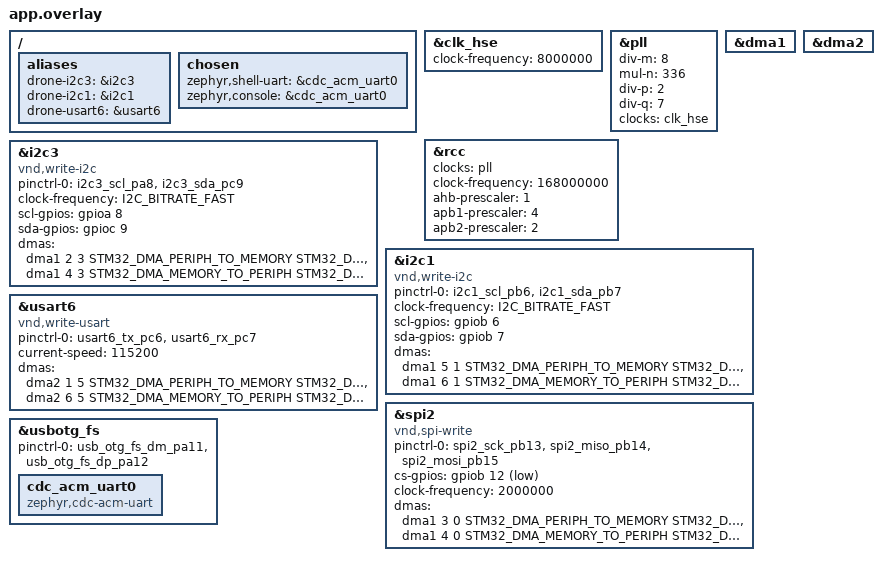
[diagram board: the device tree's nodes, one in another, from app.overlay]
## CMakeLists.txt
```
cmake_minimum_required(VERSION 3.20.0)

list(APPEND DTS_ROOTS "${CMAKE_CURRENT_SOURCE_DIR}")

# Tự động tìm kiếm cấu hình môi trường gốc của Zephyr OS
find_package(Zephyr REQUIRED HINTS $ENV{ZEPHYR_BASE})

project(Drone_Mini_Ver2)

# Ép sinh ra file compile_commands.json để VS Code hết gạch đỏ
set(CMAKE_EXPORT_COMPILE_COMMANDS ON CACHE INTERNAL "")

zephyr_include_directories(
    src
    src/Initialize
    src/RTOS
    src/Radio_Communication
    src/BMI088_Library
    src/INA226
    src/HMC5883
    src/PMW3901
    src/BMP280
    src/PWM_Control
    src/I2C_Progress
    src/Ranging_Sensor
    src/Ranging_Sensor/core/inc
    src/Ranging_Sensor/core/src
    src/USB_Debugging
    src/Extended_Kalman_Filter
    src/PID
)

# Khai báo nguồn file .c
file(GLOB_RECURSE ALL_SOURCES
    src/*.c
    BMI088_Library/*.c
    RTOS/*.c
    Initialize/*.c
    PWM_Control/*.c
    Radio_Communication/*.c
    PMW3901/*.c
    BMP280/*.c
    INA226/*.c
    HMC5883/*.c
    AT24LC/*.c
    PMW_Control/*.c
    I2C_Progress/*.c
    Ranging_Sensor/*.c
    Ranging_Sensor/core/src/*.c
    USB_Debugging/*.c
    Extended_Kalman_Filter/*.c
    PID/*.c
)

target_sources(app PRIVATE ${ALL_SOURCES})
```

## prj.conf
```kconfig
CONFIG_DYNAMIC_INTERRUPTS=y
CONFIG_SYS_CLOCK_TICKS_PER_SEC=1000
CONFIG_FPU=y
CONFIG_MAIN_STACK_SIZE=2048
CONFIG_SYSTEM_WORKQUEUE_PRIORITY=2

# RTT CONSOLE
CONFIG_USE_SEGGER_RTT=y
CONFIG_RTT_CONSOLE=y
CONFIG_CONSOLE=y
CONFIG_STDOUT_CONSOLE=y
CONFIG_PRINTK=y
CONFIG_SEGGER_RTT_BUFFER_SIZE_UP=1024

CONFIG_GPIO=y
# event & thread info
CONFIG_EVENTS=y
CONFIG_PINCTRL=y
CONFIG_THREAD_STACK_INFO=y
CONFIG_INIT_STACKS=y
CONFIG_THREAD_MONITOR=y

# --- BẬT DRIVER SERIAL & USB CDC ACM ---
CONFIG_SERIAL=y
CONFIG_UART_LINE_CTRL=y
CONFIG_USB_DEVICE_STACK=y
CONFIG_USB_DEVICE_PRODUCT="Drone Shell Console"
CONFIG_USB_CDC_ACM=y
CONFIG_USB_DEVICE_INITIALIZE_AT_BOOT=y


# --- BẬT ZEPHYR SHELL ---
CONFIG_SHELL=y
CONFIG_SHELL_BACKEND_SERIAL=y
CONFIG_SHELL_PROMPT_UART="drone:~$ "
CONFIG_SHELL_STACK_SIZE=3072
CONFIG_CBPRINTF_FP_SUPPORT=y
```

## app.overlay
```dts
#include <zephyr/dt-bindings/pinctrl/stm32-pinctrl.h>
#include <zephyr/dt-bindings/dma/stm32_dma.h>


&clk_hse {
    clock-frequency = <8000000>;
    status = "okay";
};

/* Cấu hình các hệ số PLL để kích lên 168 MHz */
&pll {
    div-m = <8>;        /* 8 MHz / 8 = 1 MHz (Chuẩn VCO input) */
    mul-n = <336>;      /* 1 MHz * 336 = 336 MHz (Chuẩn VCO output) */
    div-p = <2>;        /* 336 MHz / 2 = 168 MHz SYSCLK */
    div-q = <7>;        /* 336 MHz / 7 = 48 MHz */
    clocks = <&clk_hse>;
    status = "okay";
};

/* Xác nhận với Zephyr là CPU đang chạy ở 168 MHz */
&rcc {
    clocks = <&pll>;
    clock-frequency = <168000000>; /* Xác nhận SYSCLK = 168 MHz */
    ahb-prescaler = <1>;           /* HCLK = 168 MHz */
    apb1-prescaler = <4>;          /* PCLK1 = 42 MHz (Dành cho I2C) */
    apb2-prescaler = <2>;          /* PCLK2 = 84 MHz */
};

/ {
    aliases {
        drone-i2c3 = &i2c3;
        drone-i2c1 = &i2c1;
        drone-usart6 = &usart6;
    };
};

&dma1 {
    status = "okay";
};

&dma2 {
    status = "okay";
};

&i2c3 {
    status = "okay";
    compatible = "vnd,write-i2c";
    pinctrl-0 = <&i2c3_scl_pa8 &i2c3_sda_pc9>;
    pinctrl-names = "default";
    clock-frequency = <I2C_BITRATE_FAST>;

    scl-gpios = <&gpioa 8 (GPIO_ACTIVE_HIGH | GPIO_OPEN_DRAIN)>;
    sda-gpios = <&gpioc 9 (GPIO_ACTIVE_HIGH | GPIO_OPEN_DRAIN)>;

    dmas = <&dma1 2 3 STM32_DMA_PERIPH_TO_MEMORY STM32_DMA_PRIORITY_HIGH>,
           <&dma1 4 3 STM32_DMA_MEMORY_TO_PERIPH STM32_DMA_PRIORITY_HIGH>;
    dma-names = "rx", "tx";
};

&i2c1 {
    status = "okay";
    compatible = "vnd,write-i2c";
    pinctrl-0 = <&i2c1_scl_pb6 &i2c1_sda_pb7>;
    pinctrl-names = "default";
    clock-frequency = <I2C_BITRATE_FAST>;

    scl-gpios = <&gpiob 6 (GPIO_ACTIVE_HIGH | GPIO_OPEN_DRAIN)>;
    sda-gpios = <&gpiob 7 (GPIO_ACTIVE_HIGH | GPIO_OPEN_DRAIN)>;

    dmas = <&dma1 5 1 STM32_DMA_PERIPH_TO_MEMORY STM32_DMA_PRIORITY_HIGH>,
           <&dma1 6 1 STM32_DMA_MEMORY_TO_PERIPH STM32_DMA_PRIORITY_HIGH>;
    dma-names = "rx", "tx";
};

&usart6 {
    status = "okay";
    compatible = "vnd,write-usart";
    /delete-property/ interrupts;
    pinctrl-0 = <&usart6_tx_pc6 &usart6_rx_pc7>;
    pinctrl-names = "default";
    current-speed = <115200>;

    dmas = <&dma2 1 5 STM32_DMA_PERIPH_TO_MEMORY STM32_DMA_PRIORITY_HIGH>,
           <&dma2 6 5 STM32_DMA_MEMORY_TO_PERIPH STM32_DMA_PRIORITY_HIGH>;
    dma-names = "rx", "tx";
};

&spi2 {
    status = "okay";
    compatible = "vnd,spi-write";
    pinctrl-0 = <&spi2_sck_pb13 &spi2_miso_pb14 &spi2_mosi_pb15>;
    pinctrl-names = "default";
    cs-gpios = <&gpiob 12 GPIO_ACTIVE_LOW>;
    clock-frequency = <2000000>; /* Tần số 2MHz */

    dmas = <&dma1 3 0 STM32_DMA_PERIPH_TO_MEMORY STM32_DMA_PRIORITY_HIGH>,
           <&dma1 4 0 STM32_DMA_MEMORY_TO_PERIPH STM32_DMA_PRIORITY_HIGH>;
    dma-names = "rx", "tx";
};

/ {
    chosen {
        /* Chỉ định Zephyr Shell và Console sử dụng Virtual COM Port qua USB */
        zephyr,shell-uart = &cdc_acm_uart0;
        zephyr,console = &cdc_acm_uart0;
    };
};

&usbotg_fs {
    status = "okay";

    pinctrl-0 = <&usb_otg_fs_dm_pa11 &usb_otg_fs_dp_pa12>;
    pinctrl-names = "default";
    
    /delete-property/ vbus-gpios;

    cdc_acm_uart0: cdc_acm_uart0 {
        compatible = "zephyr,cdc-acm-uart";
    };
};
```

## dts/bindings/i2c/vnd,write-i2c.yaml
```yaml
description: Custom Bare-Metal I2C Controller Driver for Drone

compatible: "vnd,write-i2c"

include: [i2c-controller.yaml, pinctrl-device.yaml]

properties:
  reg:
    required: true
  clock-frequency:
    required: true
  scl-gpios:
    type: phandle-array
    required: false
  sda-gpios:
    type: phandle-array
    required: false
  dmas:
    type: phandle-array
    required: false
  dma-names:
    type: string-array
    required: false
```

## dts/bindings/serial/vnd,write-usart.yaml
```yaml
description: Custom Bare-Metal USART Driver with Manual DMA for Drone

compatible: "vnd,write-usart"

include: [base.yaml, pinctrl-device.yaml]

properties:
  reg:
    required: true
    
  resets:
    type: phandle-array
    required: false

  interrupts:
    type: array
    required: false

  current-speed:
    type: int
    required: false

  dmas:
    type: phandle-array
    required: false

  dma-names:
    type: string-array
    required: false
```

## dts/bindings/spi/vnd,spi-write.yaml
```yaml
description: Custom SPI Bare-metal Driver Binding

compatible: "vnd,spi-write"

include: [spi-controller.yaml, base.yaml]

properties:
  clock-frequency:
    type: int
    required: true
    description: SPI Clock frequency in Hz

  pinctrl-0:
    type: phandles
    required: true

  pinctrl-names:
    type: string-array    # <-- SỬA TẠI ĐÂY (đổi string-list thành string-array)
    required: true

  cs-gpios:
    type: phandle-array
    required: false
    description: GPIO pin for Chip Select
```

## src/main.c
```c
#include "stdio.h"
#include "Initialize/Init_reg.h"
#include <stdint.h>
#include "string.h"
#include <zephyr/devicetree.h>
#include "zephyr/device.h"
#include "zephyr/kernel.h"
#include "Radio_communication/Radio_Communication.h"
#include "I2C_Progress/I2C.h"
#include "PMW3901/pmw3901.h"
#include "USB_Debugging/usb_debug.h"


int main(void)
{
    // init_usb_shell();
    BUS_Init();
    Init_The_Config_Of_Drone();
    for(int i = 0; i < 2;i++) {
        GPIOC->ODR ^= (1 << 1); // toggle led
        k_msleep(100);
    }
    The_First_State();
    return 0;
}
```
